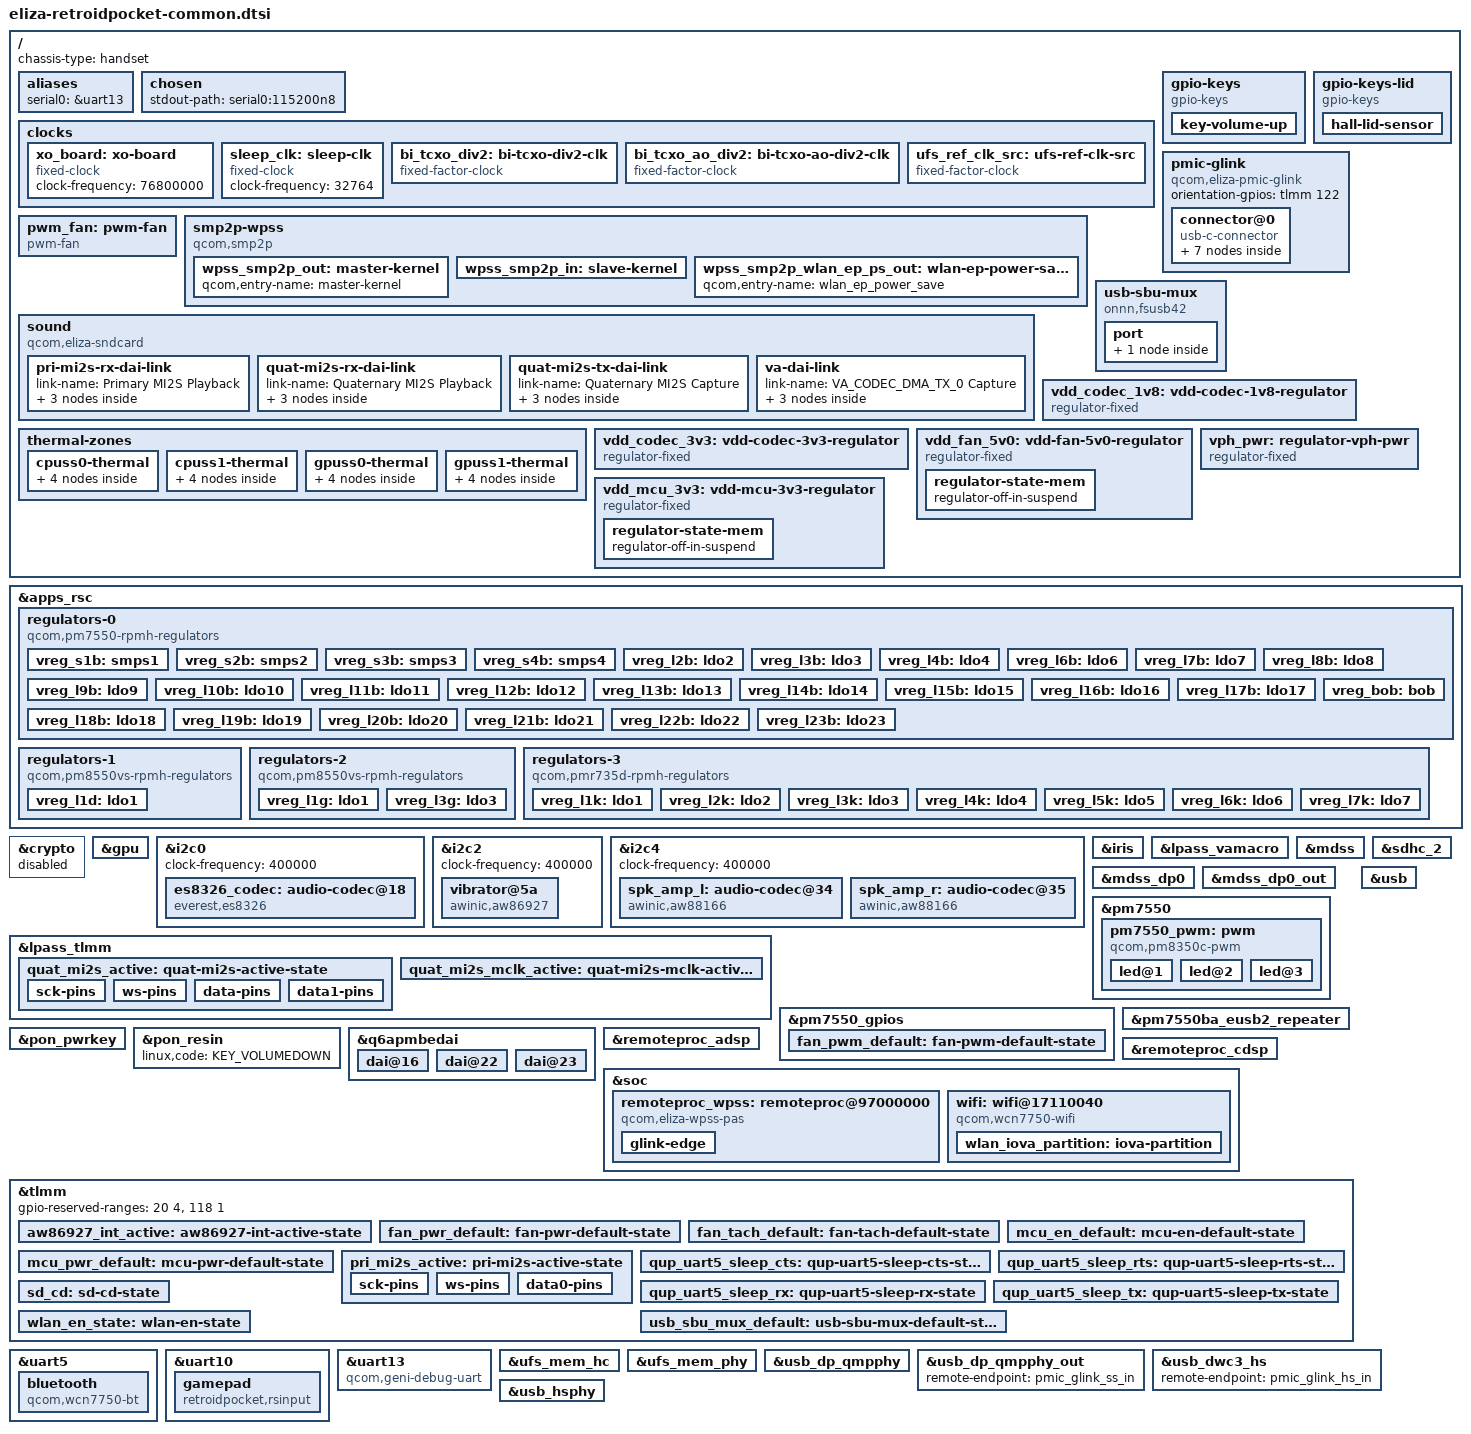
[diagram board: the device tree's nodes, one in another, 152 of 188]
// SPDX-License-Identifier: BSD-3-Clause
/*
 * Copyright (c) 2026, Teguh Sobirin.
 */

#include <dt-bindings/gpio/gpio.h>
#include <dt-bindings/leds/common.h>
#include <dt-bindings/pinctrl/qcom,pmic-gpio.h>
#include <dt-bindings/regulator/qcom,rpmh-regulator.h>
#include "eliza.dtsi"
#include "pm7550ba-eliza.dtsi"
#include "pm7550-eliza.dtsi"
#include "pm8550vs-d-eliza.dtsi"
#include "pm8550vs-g-eliza.dtsi"
#include "pmr735d-eliza.dtsi"
#include "pmk8550-eliza.dtsi"

/ {
	chassis-type = "handset";

	aliases {
		serial0 = &uart13;
	};

	chosen {
		stdout-path = "serial0:115200n8";
	};

	clocks {
		xo_board: xo-board {
			compatible = "fixed-clock";
			clock-frequency = <76800000>;
			#clock-cells = <0>;
		};

		sleep_clk: sleep-clk {
			compatible = "fixed-clock";
			clock-frequency = <32764>;
			#clock-cells = <0>;
		};

		bi_tcxo_div2: bi-tcxo-div2-clk {
			compatible = "fixed-factor-clock";
			#clock-cells = <0>;

			clocks = <&rpmhcc RPMH_CXO_CLK>;
			clock-mult = <1>;
			clock-div = <2>;
		};

		bi_tcxo_ao_div2: bi-tcxo-ao-div2-clk {
			compatible = "fixed-factor-clock";
			#clock-cells = <0>;

			clocks = <&rpmhcc RPMH_CXO_CLK_A>;
			clock-mult = <1>;
			clock-div = <2>;
		};

		ufs_ref_clk_src: ufs-ref-clk-src {
			compatible = "fixed-factor-clock";
			#clock-cells = <0>;

			clocks = <&rpmhcc RPMH_LN_BB_CLK3>;
			clock-mult = <1>;
			clock-div = <2>;
		};
	};

	gpio-keys {
		compatible = "gpio-keys";

		key-volume-up {
			label = "Volume Up";
			linux,code = <KEY_VOLUMEUP>;
			gpios = <&pm7550_gpios 6 GPIO_ACTIVE_LOW>;
			debounce-interval = <10>;
			linux,can-disable;
			wakeup-source;
		};
	};

	gpio-keys-lid {
		compatible = "gpio-keys";

		hall-lid-sensor {
			label = "Hall Lid Sensor";
			gpios = <&tlmm 31 GPIO_ACTIVE_LOW>;
			linux,input-type = <EV_SW>;
			linux,code = <SW_LID>;
			linux,can-disable;
			wakeup-source;
		};
	};

	pmic-glink {
		compatible = "qcom,eliza-pmic-glink",
			     "qcom,sm8550-pmic-glink",
			     "qcom,pmic-glink";
		#address-cells = <1>;
		#size-cells = <0>;
		orientation-gpios = <&tlmm 122 GPIO_ACTIVE_HIGH>;

		connector@0 {
			compatible = "usb-c-connector";
			reg = <0>;

			power-role = "dual";
			data-role = "dual";

			ports {
				#address-cells = <1>;
				#size-cells = <0>;

				port@0 {
					reg = <0>;

					pmic_glink_hs_in: endpoint {
						remote-endpoint = <&usb_dwc3_hs>;
					};
				};

				port@1 {
					reg = <1>;

					pmic_glink_ss_in: endpoint {
						remote-endpoint = <&usb_dp_qmpphy_out>;
					};
				};

				port@2 {
					reg = <2>;

					pmic_glink_sbu: endpoint {
						remote-endpoint = <&usb_sbu_mux_endpoint>;
					};
				};
			};
		};
	};

	pwm_fan: pwm-fan {
		compatible = "pwm-fan";

		fan-supply = <&vdd_fan_5v0>;
		pwms = <&pm7550_pwm 3 40000>;

		cooling-levels = <0 30 45 60 70 90 120 150>;
		#cooling-cells = <2>;

		pinctrl-names = "default";
		pinctrl-0 = <&fan_pwm_default>, <&fan_tach_default>;

		pulses-per-revolution = <2>;
		interrupt-parent = <&tlmm>;
		interrupts = <3 IRQ_TYPE_EDGE_FALLING>;
	};

	smp2p-wpss {
		compatible = "qcom,smp2p";
		qcom,smem = <617>, <616>;

		interrupts-extended = <&ipcc IPCC_CLIENT_WPSS
					     IPCC_MPROC_SIGNAL_SMP2P
					     IRQ_TYPE_EDGE_RISING>;

		mboxes = <&ipcc IPCC_CLIENT_WPSS IPCC_MPROC_SIGNAL_SMP2P>;

		qcom,local-pid = <0>;
		qcom,remote-pid = <13>;

		wpss_smp2p_out: master-kernel {
			qcom,entry-name = "master-kernel";
			#qcom,smem-state-cells = <1>;
		};

		wpss_smp2p_in: slave-kernel {
			qcom,entry-name = "slave-kernel";
			interrupt-controller;
			#interrupt-cells = <2>;
		};

		wpss_smp2p_wlan_ep_ps_out: wlan-ep-power-save {
			qcom,entry-name = "wlan_ep_power_save";
			#qcom,smem-state-cells = <1>;
		};
	};

	sound {
		compatible = "qcom,eliza-sndcard", "qcom,sm8450-sndcard";
		model = "ELIZA-RetroidPocket-I2S";

		pinctrl-names = "default";
		pinctrl-0 = <&pri_mi2s_active>, <&quat_mi2s_active>,
			    <&quat_mi2s_mclk_active>;

		pri-mi2s-rx-dai-link {
			link-name = "Primary MI2S Playback";

			cpu {
				sound-dai = <&q6apmbedai PRIMARY_MI2S_RX>;
			};

			platform {
				sound-dai = <&q6apm>;
			};

			codec {
				sound-dai = <&spk_amp_l 0>, <&spk_amp_r 0>;
			};
		};

		quat-mi2s-rx-dai-link {
			link-name = "Quaternary MI2S Playback";

			cpu {
				sound-dai = <&q6apmbedai QUATERNARY_MI2S_RX>;
			};

			platform {
				sound-dai = <&q6apm>;
			};

			codec {
				sound-dai = <&es8326_codec>;
			};
		};

		quat-mi2s-tx-dai-link {
			link-name = "Quaternary MI2S Capture";

			cpu {
				sound-dai = <&q6apmbedai QUATERNARY_MI2S_TX>;
			};

			platform {
				sound-dai = <&q6apm>;
			};

			codec {
				sound-dai = <&es8326_codec>;
			};
		};

		va-dai-link {
			link-name = "VA_CODEC_DMA_TX_0 Capture";

			cpu {
				sound-dai = <&q6apmbedai VA_CODEC_DMA_TX_0>;
			};

			platform {
				sound-dai = <&q6apm>;
			};

			codec {
				sound-dai = <&lpass_vamacro 0>;
			};
		};
	};

	thermal-zones {
		cpuss0-thermal {
			trips {
				cpuss0_fan: fan-trip {
					temperature = <55000>;
					hysteresis = <5000>;
					type = "active";
				};
			};

			cooling-maps {
				map-fan {
					trip = <&cpuss0_fan>;
					cooling-device = <&pwm_fan THERMAL_NO_LIMIT THERMAL_NO_LIMIT>;
				};
			};
		};

		cpuss1-thermal {
			trips {
				cpuss1_fan: fan-trip {
					temperature = <55000>;
					hysteresis = <5000>;
					type = "active";
				};
			};

			cooling-maps {
				map-fan {
					trip = <&cpuss1_fan>;
					cooling-device = <&pwm_fan THERMAL_NO_LIMIT THERMAL_NO_LIMIT>;
				};
			};
		};

		gpuss0-thermal {
			trips {
				gpuss0_fan: fan-trip {
					temperature = <60000>;
					hysteresis = <5000>;
					type = "active";
				};
			};

			cooling-maps {
				map-fan {
					trip = <&gpuss0_fan>;
					cooling-device = <&pwm_fan THERMAL_NO_LIMIT THERMAL_NO_LIMIT>;
				};
			};
		};

		gpuss1-thermal {
			trips {
				gpuss1_fan: fan-trip {
					temperature = <60000>;
					hysteresis = <5000>;
					type = "active";
				};
			};

			cooling-maps {
				map-fan {
					trip = <&gpuss1_fan>;
					cooling-device = <&pwm_fan THERMAL_NO_LIMIT THERMAL_NO_LIMIT>;
				};
			};
		};
	};

	/*
	 * DP AUX (SBU1/SBU2) analog switch, controlled by the same two GPIOs
	 * the vendor DP driver drives: gpio75 = output enable (driven low
	 * when DP is active), gpio76 = SBU lane select, high for a flipped
	 * (CC2) plug. The exact switch part is not known; the driver only
	 * binds against the generic gpio-sbu-mux compatible.
	 */
	usb-sbu-mux {
		compatible = "onnn,fsusb42", "gpio-sbu-mux";

		enable-gpios = <&tlmm 75 GPIO_ACTIVE_LOW>;
		select-gpios = <&tlmm 76 GPIO_ACTIVE_HIGH>;

		pinctrl-names = "default";
		pinctrl-0 = <&usb_sbu_mux_default>;

		mode-switch;
		orientation-switch;

		port {
			usb_sbu_mux_endpoint: endpoint {
				remote-endpoint = <&pmic_glink_sbu>;
			};
		};
	};

	vdd_codec_1v8: vdd-codec-1v8-regulator {
		compatible = "regulator-fixed";
		regulator-name = "vdd_codec_1v8";

		regulator-min-microvolt = <1800000>;
		regulator-max-microvolt = <1800000>;

		gpio = <&tlmm 163 GPIO_ACTIVE_HIGH>;
		enable-active-high;
	};

	vdd_codec_3v3: vdd-codec-3v3-regulator {
		compatible = "regulator-fixed";
		regulator-name = "vdd_codec_3v3";

		regulator-min-microvolt = <3300000>;
		regulator-max-microvolt = <3300000>;

		gpio = <&tlmm 164 GPIO_ACTIVE_HIGH>;
		enable-active-high;
	};

	vdd_fan_5v0: vdd-fan-5v0-regulator {
		compatible = "regulator-fixed";
		regulator-name = "vdd_fan_5v0";

		regulator-min-microvolt = <5000000>;
		regulator-max-microvolt = <5000000>;

		gpio = <&tlmm 55 GPIO_ACTIVE_HIGH>;
		enable-active-high;

		pinctrl-names = "default";
		pinctrl-0 = <&fan_pwr_default>;

		regulator-state-mem {
			regulator-off-in-suspend;
		};
	};

	vdd_mcu_3v3: vdd-mcu-3v3-regulator {
		compatible = "regulator-fixed";
		regulator-name = "vdd_mcu_3v3";

		regulator-min-microvolt = <3300000>;
		regulator-max-microvolt = <3300000>;

		gpio = <&tlmm 54 GPIO_ACTIVE_HIGH>;
		enable-active-high;

		pinctrl-names = "default";
		pinctrl-0 = <&mcu_pwr_default>;

		regulator-state-mem {
			regulator-off-in-suspend;
		};
	};

	vph_pwr: regulator-vph-pwr {
		compatible = "regulator-fixed";

		regulator-name = "vph_pwr";
		regulator-min-microvolt = <3700000>;
		regulator-max-microvolt = <3700000>;

		regulator-always-on;
		regulator-boot-on;
	};
};

&apps_rsc {
	regulators-0 {
		compatible = "qcom,pm7550-rpmh-regulators";

		vdd-l1-supply = <&vreg_s3b>;
		vdd-l2-l3-supply = <&vreg_s3b>;
		vdd-l4-l5-supply = <&vreg_s2b>;
		vdd-l6-supply = <&vreg_s2b>;
		vdd-l7-supply = <&vreg_s1b>;
		vdd-l8-supply = <&vreg_s1b>;
		vdd-l9-l10-supply = <&vreg_s1b>;
		vdd-l11-supply = <&vreg_s1b>;
		vdd-l12-l14-supply = <&vreg_bob>;
		vdd-l13-l16-supply = <&vreg_bob>;
		vdd-l15-l17-l18-l19-l20-l21-l22-l23-supply = <&vreg_bob>;
		vdd-s1-supply = <&vph_pwr>;
		vdd-s2-supply = <&vph_pwr>;
		vdd-s3-supply = <&vph_pwr>;
		vdd-s4-supply = <&vph_pwr>;
		vdd-s5-supply = <&vph_pwr>;
		vdd-s6-supply = <&vph_pwr>;

		vdd-bob-supply = <&vph_pwr>;

		qcom,pmic-id = "b";

		vreg_s1b: smps1 {
			regulator-name = "vreg_s1b";
			regulator-min-microvolt = <1856000>;
			regulator-max-microvolt = <2040000>;
			regulator-initial-mode = <RPMH_REGULATOR_MODE_HPM>;
		};

		vreg_s2b: smps2 {
			regulator-name = "vreg_s2b";
			regulator-min-microvolt = <1256000>;
			regulator-max-microvolt = <1408000>;
			regulator-initial-mode = <RPMH_REGULATOR_MODE_HPM>;
		};

		vreg_s3b: smps3 {
			regulator-name = "vreg_s3b";
			regulator-min-microvolt = <880000>;
			regulator-max-microvolt = <1040000>;
			regulator-initial-mode = <RPMH_REGULATOR_MODE_HPM>;
		};

		vreg_s4b: smps4 {
			regulator-name = "vreg_s4b";
			regulator-min-microvolt = <2156000>;
			regulator-max-microvolt = <2600000>;
			regulator-initial-mode = <RPMH_REGULATOR_MODE_HPM>;
		};

		vreg_l2b: ldo2 {
			regulator-name = "vreg_l2b";
			regulator-min-microvolt = <720000>;
			regulator-max-microvolt = <950000>;
			regulator-initial-mode = <RPMH_REGULATOR_MODE_HPM>;
		};

		vreg_l3b: ldo3 {
			regulator-name = "vreg_l3b";
			regulator-min-microvolt = <880000>;
			regulator-max-microvolt = <912000>;
			regulator-initial-mode = <RPMH_REGULATOR_MODE_HPM>;
		};

		vreg_l4b: ldo4 {
			regulator-name = "vreg_l4b";
			regulator-min-microvolt = <1200000>;
			regulator-max-microvolt = <1200000>;
			regulator-initial-mode = <RPMH_REGULATOR_MODE_HPM>;
		};

		vreg_l6b: ldo6 {
			regulator-name = "vreg_l6b";
			regulator-min-microvolt = <866000>;
			regulator-max-microvolt = <958000>;
			regulator-initial-mode = <RPMH_REGULATOR_MODE_HPM>;
		};

		vreg_l7b: ldo7 {
			regulator-name = "vreg_l7b";
			regulator-min-microvolt = <1800000>;
			regulator-max-microvolt = <1800000>;
			regulator-initial-mode = <RPMH_REGULATOR_MODE_HPM>;
		};

		vreg_l8b: ldo8 {
			regulator-name = "vreg_l8b";
			regulator-min-microvolt = <1800000>;
			regulator-max-microvolt = <1800000>;
			regulator-initial-mode = <RPMH_REGULATOR_MODE_HPM>;
		};

		vreg_l9b: ldo9 {
			regulator-name = "vreg_l9b";
			regulator-min-microvolt = <1800000>;
			regulator-max-microvolt = <1800000>;
			regulator-initial-mode = <RPMH_REGULATOR_MODE_HPM>;
		};

		vreg_l10b: ldo10 {
			regulator-name = "vreg_l10b";
			regulator-min-microvolt = <1800000>;
			regulator-max-microvolt = <1800000>;
			regulator-initial-mode = <RPMH_REGULATOR_MODE_HPM>;
		};

		vreg_l11b: ldo11 {
			regulator-name = "vreg_l11b";
			regulator-min-microvolt = <1800000>;
			regulator-max-microvolt = <1800000>;
			regulator-initial-mode = <RPMH_REGULATOR_MODE_HPM>;
		};

		vreg_l12b: ldo12 {
			regulator-name = "vreg_l12b";
			/* Voltage range for UFS 3.x and above */
			regulator-min-microvolt = <2400000>;
			regulator-max-microvolt = <3300000>;
			regulator-initial-mode = <RPMH_REGULATOR_MODE_HPM>;
		};

		vreg_l13b: ldo13 {
			regulator-name = "vreg_l13b";
			regulator-min-microvolt = <2700000>;
			regulator-max-microvolt = <3300000>;
			regulator-initial-mode = <RPMH_REGULATOR_MODE_HPM>;
		};

		vreg_l14b: ldo14 {
			regulator-name = "vreg_l14b";
			regulator-min-microvolt = <3300000>;
			regulator-max-microvolt = <3304000>;
			regulator-initial-mode = <RPMH_REGULATOR_MODE_HPM>;
		};

		vreg_l15b: ldo15 {
			regulator-name = "vreg_l15b";
			regulator-min-microvolt = <3300000>;
			regulator-max-microvolt = <3304000>;
			regulator-initial-mode = <RPMH_REGULATOR_MODE_HPM>;
		};

		vreg_l16b: ldo16 {
			regulator-name = "vreg_l16b";
			regulator-min-microvolt = <3008000>;
			regulator-max-microvolt = <3008000>;
			regulator-initial-mode = <RPMH_REGULATOR_MODE_HPM>;
		};

		vreg_l17b: ldo17 {
			regulator-name = "vreg_l17b";
			regulator-min-microvolt = <3104000>;
			regulator-max-microvolt = <3104000>;
			regulator-initial-mode = <RPMH_REGULATOR_MODE_HPM>;
		};

		vreg_l18b: ldo18 {
			regulator-name = "vreg_l18b";
			regulator-min-microvolt = <2800000>;
			regulator-max-microvolt = <2800000>;
			regulator-initial-mode = <RPMH_REGULATOR_MODE_HPM>;
		};

		vreg_l19b: ldo19 {
			regulator-name = "vreg_l19b";
			regulator-min-microvolt = <3000000>;
			regulator-max-microvolt = <3000000>;
			regulator-initial-mode = <RPMH_REGULATOR_MODE_HPM>;
		};

		vreg_l20b: ldo20 {
			regulator-name = "vreg_l20b";
			regulator-min-microvolt = <1620000>;
			regulator-max-microvolt = <3544000>;
			regulator-initial-mode = <RPMH_REGULATOR_MODE_HPM>;
		};

		vreg_l21b: ldo21 {
			regulator-name = "vreg_l21b";
			regulator-min-microvolt = <1620000>;
			regulator-max-microvolt = <3544000>;
			regulator-initial-mode = <RPMH_REGULATOR_MODE_HPM>;
		};

		vreg_l22b: ldo22 {
			regulator-name = "vreg_l22b";
			regulator-min-microvolt = <2700000>;
			regulator-max-microvolt = <3400000>;
			regulator-initial-mode = <RPMH_REGULATOR_MODE_HPM>;
		};

		vreg_l23b: ldo23 {
			regulator-name = "vreg_l23b";
			regulator-min-microvolt = <1650000>;
			regulator-max-microvolt = <3544000>;
			regulator-initial-mode = <RPMH_REGULATOR_MODE_HPM>;
		};

		vreg_bob: bob {
			regulator-name = "vreg_bob";
			regulator-min-microvolt = <3008000>;
			regulator-max-microvolt = <3960000>;
			regulator-initial-mode = <RPMH_REGULATOR_MODE_HPM>;
		};
	};

	regulators-1 {
		compatible = "qcom,pm8550vs-rpmh-regulators";

		vdd-l1-supply = <&vreg_s1b>;

		qcom,pmic-id = "d";

		vreg_l1d: ldo1 {
			regulator-name = "vreg_l1d";
			regulator-min-microvolt = <1800000>;
			regulator-max-microvolt = <1800000>;
			regulator-initial-mode = <RPMH_REGULATOR_MODE_HPM>;
		};
	};

	regulators-2 {
		compatible = "qcom,pm8550vs-rpmh-regulators";

		vdd-l1-supply = <&vreg_s2b>;
		vdd-l3-supply = <&vreg_s2b>;

		qcom,pmic-id = "g";

		vreg_l1g: ldo1 {
			regulator-name = "vreg_l1g";
			regulator-min-microvolt = <1150000>;
			regulator-max-microvolt = <1260000>;
			regulator-initial-mode = <RPMH_REGULATOR_MODE_HPM>;
		};

		vreg_l3g: ldo3 {
			regulator-name = "vreg_l3g";
			regulator-min-microvolt = <1150000>;
			regulator-max-microvolt = <1260000>;
			regulator-initial-mode = <RPMH_REGULATOR_MODE_HPM>;
		};

	};

	regulators-3 {
		compatible = "qcom,pmr735d-rpmh-regulators";

		vdd-l1-l2-l5-supply = <&vreg_s3b>;
		vdd-l3-l4-supply = <&vreg_s2b>;
		vdd-l6-supply = <&vreg_s1b>;
		vdd-l7-supply = <&vreg_s3b>;

		qcom,pmic-id = "k";

		vreg_l1k: ldo1 {
			regulator-name = "vreg_l1k";
			regulator-min-microvolt = <488000>;
			regulator-max-microvolt = <912000>;
			regulator-initial-mode = <RPMH_REGULATOR_MODE_HPM>;
		};

		vreg_l2k: ldo2 {
			regulator-name = "vreg_l2k";
			regulator-min-microvolt = <920000>;
			regulator-max-microvolt = <969000>;
			regulator-initial-mode = <RPMH_REGULATOR_MODE_HPM>;
		};

		vreg_l3k: ldo3 {
			regulator-name = "vreg_l3k";
			regulator-min-microvolt = <1080000>;
			regulator-max-microvolt = <1350000>;
			regulator-initial-mode = <RPMH_REGULATOR_MODE_HPM>;
		};

		vreg_l4k: ldo4 {
			regulator-name = "vreg_l4k";
			regulator-min-microvolt = <960000>;
			regulator-max-microvolt = <1200000>;
			regulator-initial-mode = <RPMH_REGULATOR_MODE_HPM>;
		};

		vreg_l5k: ldo5 {
			regulator-name = "vreg_l5k";
			regulator-min-microvolt = <866000>;
			regulator-max-microvolt = <931000>;
			regulator-initial-mode = <RPMH_REGULATOR_MODE_HPM>;
		};

		vreg_l6k: ldo6 {
			regulator-name = "vreg_l6k";
			regulator-min-microvolt = <1100000>;
			regulator-max-microvolt = <2000000>;
			regulator-initial-mode = <RPMH_REGULATOR_MODE_HPM>;
		};

		vreg_l7k: ldo7 {
			regulator-name = "vreg_l7k";
			regulator-min-microvolt = <720000>;
			regulator-max-microvolt = <958000>;
			regulator-initial-mode = <RPMH_REGULATOR_MODE_HPM>;
		};
	};
};

/* the QCE driver is marked BROKEN, keep the node from blocking sync_state */
&crypto {
	status = "disabled";
};

&gpu {
	status = "okay";
};

&i2c0 {
	clock-frequency = <400000>;
	status = "okay";

	es8326_codec: audio-codec@18 {
		compatible = "everest,es8326";
		reg = <0x18>;

		clocks = <&q6prmcc LPASS_CLK_ID_MCLK_3 LPASS_CLK_ATTRIBUTE_COUPLE_NO>;
		clock-names = "mclk";
		assigned-clocks = <&q6prmcc LPASS_CLK_ID_MCLK_3 LPASS_CLK_ATTRIBUTE_COUPLE_NO>;
		assigned-clock-rates = <12288000>;

		interrupt-parent = <&tlmm>;
		interrupts = <98 IRQ_TYPE_EDGE_RISING>;

		vdd-supply = <&vdd_codec_3v3>;
		vddio-supply = <&vdd_codec_1v8>;

		everest,jack-detect-inverted;
		everest,interrupt-src = /bits/ 8 <0x08>;
		everest,interrupt-clk = /bits/ 8 <0x00>;

		#sound-dai-cells = <0>;
	};
};

&i2c2 {
	clock-frequency = <400000>;
	status = "okay";

	vibrator@5a {
		compatible = "awinic,aw86927";
		reg = <0x5a>;

		interrupts-extended = <&tlmm 125 IRQ_TYPE_EDGE_FALLING>;
		reset-gpios = <&tlmm 68 GPIO_ACTIVE_LOW>;

		pinctrl-0 = <&aw86927_int_active>;
		pinctrl-names = "default";
	};
};

&i2c4 {
	clock-frequency = <400000>;
	status = "okay";

	spk_amp_l: audio-codec@34 {
		compatible = "awinic,aw88166";
		reg = <0x34>;
		#sound-dai-cells = <1>;
		reset-gpios = <&tlmm 127 GPIO_ACTIVE_LOW>;
		awinic,audio-channel = <1>;
		awinic,sync-flag;
		sound-name-prefix = "SPK_L";
	};

	spk_amp_r: audio-codec@35 {
		compatible = "awinic,aw88166";
		reg = <0x35>;
		#sound-dai-cells = <1>;
		reset-gpios = <&tlmm 126 GPIO_ACTIVE_LOW>;
		awinic,audio-channel = <0>;
		awinic,sync-flag;
		sound-name-prefix = "SPK_R";
	};
};

&iris {
	status = "okay";
};

&lpass_tlmm {
	quat_mi2s_active: quat-mi2s-active-state {
		sck-pins {
			pins = "gpio0";
			function = "i2s0_clk";
			drive-strength = <8>;
			bias-disable;
			output-high;
		};

		ws-pins {
			pins = "gpio1";
			function = "i2s0_ws";
			drive-strength = <8>;
			bias-disable;
			output-high;
		};

		data-pins {
			pins = "gpio2";
			function = "i2s0_data";
			drive-strength = <8>;
			bias-disable;
		};

		data1-pins {
			pins = "gpio3";
			function = "i2s0_data";
			drive-strength = <8>;
			bias-disable;
		};
	};

	quat_mi2s_mclk_active: quat-mi2s-mclk-active-state {
		pins = "gpio5";
		function = "ext_mclk1_c";
		drive-strength = <8>;
		bias-disable;
		output-high;
	};
};

&lpass_vamacro {
	pinctrl-names = "default";
	pinctrl-0 = <&dmic01_default>;

	vdd-micb-supply = <&vreg_l7b>;
	qcom,dmic-sample-rate = <4800000>;
};

&mdss {
	status = "okay";
};

&mdss_dp0 {
	status = "okay";
};

&mdss_dp0_out {
	link-frequencies = /bits/ 64 <1620000000 2700000000 5400000000 8100000000>;
};

&pm7550 {
	pm7550_pwm: pwm {
		compatible = "qcom,pm8350c-pwm";
		#address-cells = <1>;
		#size-cells = <0>;
		#pwm-cells = <2>;
		status = "okay";

		led@1 {
			reg = <1>;
			color = <LED_COLOR_ID_RED>;
			function = LED_FUNCTION_CHARGING;
			linux,default-trigger = "qcom-battmgr-bat-charging";
		};

		led@2 {
			reg = <2>;
			color = <LED_COLOR_ID_GREEN>;
			function = LED_FUNCTION_CHARGING;
			linux,default-trigger = "qcom-battmgr-bat-full";
		};

		led@3 {
			reg = <3>;
			color = <LED_COLOR_ID_BLUE>;
			function = LED_FUNCTION_STATUS;
		};
	};
};

&pm7550_gpios {
	fan_pwm_default: fan-pwm-default-state {
		pins = "gpio8";
		function = "func1";
		input-disable;
		output-enable;
		output-low;
		bias-disable;
		power-source = <1>;
	};
};

&pm7550ba_eusb2_repeater {
	vdd18-supply = <&vreg_l7b>;
	vdd3-supply = <&vreg_l17b>;
};

&pon_pwrkey {
	status = "okay";
};

&pon_resin {
	linux,code = <KEY_VOLUMEDOWN>;
	status = "okay";
};

&q6apmbedai {
	#address-cells = <1>;
	#size-cells = <0>;

	dai@16 {
		reg = <PRIMARY_MI2S_RX>;
		clocks = <&q6prmcc LPASS_CLK_ID_MCLK_1 LPASS_CLK_ATTRIBUTE_COUPLE_NO>,
			 <&q6prmcc LPASS_CLK_ID_PRI_MI2S_IBIT LPASS_CLK_ATTRIBUTE_COUPLE_NO>;
		clock-names = "mclk", "bclk";
	};

	dai@22 {
		reg = <QUATERNARY_MI2S_RX>;
		clocks = <&q6prmcc LPASS_CLK_ID_MCLK_3 LPASS_CLK_ATTRIBUTE_COUPLE_NO>,
			 <&q6prmcc LPASS_CLK_ID_QUAD_MI2S_IBIT LPASS_CLK_ATTRIBUTE_COUPLE_NO>;
		clock-names = "mclk", "bclk";
	};

	dai@23 {
		reg = <QUATERNARY_MI2S_TX>;
		clocks = <&q6prmcc LPASS_CLK_ID_MCLK_3 LPASS_CLK_ATTRIBUTE_COUPLE_NO>,
			 <&q6prmcc LPASS_CLK_ID_QUAD_MI2S_IBIT LPASS_CLK_ATTRIBUTE_COUPLE_NO>;
		clock-names = "mclk", "bclk";
	};
};

&remoteproc_adsp {
	status = "okay";
};

&remoteproc_cdsp {
	status = "okay";
};

&sdhc_2 {
	vmmc-supply = <&vreg_l13b>;
	vqmmc-supply = <&vreg_l23b>;

	cd-gpios = <&tlmm 58 GPIO_ACTIVE_LOW>;

	pinctrl-0 = <&sdc2_default>, <&sd_cd>;
	pinctrl-1 = <&sdc2_sleep>, <&sd_cd>;
	pinctrl-names = "default", "sleep";

	status = "okay";
};

&soc {
	/*
	 * WCN7750: the WLAN Q6 runs on the WPSS remoteproc (downstream
	 * kera-wcn7750, icnss2), booted by ath12k through qcom,rproc.
	 */
	remoteproc_wpss: remoteproc@97000000 {
		compatible = "qcom,eliza-wpss-pas", "qcom,sc7280-wpss-pas";
		reg = <0x0 0x97000000 0x0 0x10000>;

		interrupts-extended = <&intc GIC_SPI 200 IRQ_TYPE_EDGE_RISING>,
				      <&wpss_smp2p_in 0 IRQ_TYPE_EDGE_RISING>,
				      <&wpss_smp2p_in 1 IRQ_TYPE_EDGE_RISING>,
				      <&wpss_smp2p_in 2 IRQ_TYPE_EDGE_RISING>,
				      <&wpss_smp2p_in 3 IRQ_TYPE_EDGE_RISING>,
				      <&wpss_smp2p_in 7 IRQ_TYPE_EDGE_RISING>;
		interrupt-names = "wdog",
				  "fatal",
				  "ready",
				  "handover",
				  "stop-ack",
				  "shutdown-ack";

		clocks = <&rpmhcc RPMH_CXO_CLK>;
		clock-names = "xo";

		power-domains = <&rpmhpd RPMHPD_CX>,
				<&rpmhpd RPMHPD_MX>;
		power-domain-names = "cx",
				     "mx";

		memory-region = <&wpss_mem>;

		qcom,qmp = <&aoss_qmp>;

		qcom,smem-states = <&wpss_smp2p_out 0>;
		qcom,smem-state-names = "stop";

		status = "okay";

		glink-edge {
			interrupts-extended = <&ipcc IPCC_CLIENT_WPSS
						     IPCC_MPROC_SIGNAL_GLINK_QMP
						     IRQ_TYPE_EDGE_RISING>;
			mboxes = <&ipcc IPCC_CLIENT_WPSS
					IPCC_MPROC_SIGNAL_GLINK_QMP>;

			label = "wpss";
			qcom,remote-pid = <13>;
		};
	};

	wifi: wifi@17110040 {
		compatible = "qcom,wcn7750-wifi";
		/* MSI write target; the register BAR is reported over QMI */
		reg = <0x0 0x17110040 0x0 0x0>;
		reg-names = "msi_addr";

		/* MSI vectors: 10 CE + 18 DP */
		interrupts = <GIC_SPI 768 IRQ_TYPE_EDGE_RISING>,
			     <GIC_SPI 769 IRQ_TYPE_EDGE_RISING>,
			     <GIC_SPI 770 IRQ_TYPE_EDGE_RISING>,
			     <GIC_SPI 771 IRQ_TYPE_EDGE_RISING>,
			     <GIC_SPI 772 IRQ_TYPE_EDGE_RISING>,
			     <GIC_SPI 773 IRQ_TYPE_EDGE_RISING>,
			     <GIC_SPI 774 IRQ_TYPE_EDGE_RISING>,
			     <GIC_SPI 775 IRQ_TYPE_EDGE_RISING>,
			     <GIC_SPI 776 IRQ_TYPE_EDGE_RISING>,
			     <GIC_SPI 777 IRQ_TYPE_EDGE_RISING>,
			     <GIC_SPI 778 IRQ_TYPE_EDGE_RISING>,
			     <GIC_SPI 779 IRQ_TYPE_EDGE_RISING>,
			     <GIC_SPI 780 IRQ_TYPE_EDGE_RISING>,
			     <GIC_SPI 781 IRQ_TYPE_EDGE_RISING>,
			     <GIC_SPI 782 IRQ_TYPE_EDGE_RISING>,
			     <GIC_SPI 783 IRQ_TYPE_EDGE_RISING>,
			     <GIC_SPI 784 IRQ_TYPE_EDGE_RISING>,
			     <GIC_SPI 785 IRQ_TYPE_EDGE_RISING>,
			     <GIC_SPI 786 IRQ_TYPE_EDGE_RISING>,
			     <GIC_SPI 787 IRQ_TYPE_EDGE_RISING>,
			     <GIC_SPI 788 IRQ_TYPE_EDGE_RISING>,
			     <GIC_SPI 789 IRQ_TYPE_EDGE_RISING>,
			     <GIC_SPI 790 IRQ_TYPE_EDGE_RISING>,
			     <GIC_SPI 791 IRQ_TYPE_EDGE_RISING>,
			     <GIC_SPI 792 IRQ_TYPE_EDGE_RISING>,
			     <GIC_SPI 793 IRQ_TYPE_EDGE_RISING>,
			     <GIC_SPI 794 IRQ_TYPE_EDGE_RISING>,
			     <GIC_SPI 795 IRQ_TYPE_EDGE_RISING>,
			     <GIC_SPI 796 IRQ_TYPE_EDGE_RISING>,
			     <GIC_SPI 797 IRQ_TYPE_EDGE_RISING>,
			     <GIC_SPI 798 IRQ_TYPE_EDGE_RISING>,
			     <GIC_SPI 799 IRQ_TYPE_EDGE_RISING>;

		iommus = <&apps_smmu 0x1480 0x1>;
		dma-coherent;

		/* PCIe -> DDR path the companion die masters through */
		interconnects = <&pcie_noc MASTER_PCIE_0 QCOM_ICC_TAG_ALWAYS
				 &mc_virt SLAVE_EBI1 QCOM_ICC_TAG_ALWAYS>;
		interconnect-names = "pcie-mem";

		/* shared with Bluetooth, which enables them without a voltage */
		vdd-cx-mx-supply = <&vreg_s3b>;
		vdd-1.8-xo-supply = <&vreg_s1b>;
		vdd-1.3-rfa-supply = <&vreg_s2b>;
		vdd-1.8-io-supply = <&vreg_l11b>;

		qcom,rproc = <&remoteproc_wpss>;

		/* WLAN_EN, driven by the driver once the rails are up */
		wlan-en-gpios = <&tlmm 35 GPIO_ACTIVE_HIGH>;
		pinctrl-names = "default";
		pinctrl-0 = <&wlan_en_state>;

		/* wlan-en, bt-en, host-sol, dev-sol, sw-ctrl, reset-b */
		qcom,gpio-info = <35 0xffff 33 32 81 0xffff>;

		/*
		 * The die reaches host memory through a 256 MB window; the IOVA
		 * partition below confines the DMA allocator to it (downstream
		 * qcom,iommu-geometry 0xb0000000+0x10010000) and is what
		 * host_cap ddr_range reports, together with the MSA carveout.
		 */
		memory-region = <&wlan_iova_partition>, <&wlan_msa_mem>;
		memory-region-names = "iova-partition", "msa";

		/* endpoint power save on the internal PCIe link */
		qcom,smem-states = <&wpss_smp2p_wlan_ep_ps_out 0>;
		qcom,smem-state-names = "wlan-ep-powersave-smp2p-out";

		/* kera-wcn7750.dtsi qcom,pdc_init_table */
		qcom,qmp = <&aoss_qmp>;
		qcom,pdc-init-table =
			" {class: wlan_pdc, ss: rf, res: s3b.v, dwnval: 696}",
			" {class: wlan_pdc, ss: rf, res: s1b.v, upval: 1864}",
			" {class: wlan_pdc, ss: rf, res: s2b.v, upval: 1316}",
			" {class: wlan_pdc, ss: rf, res: s4b.e, enable: 0}";

		status = "okay";

		wlan_iova_partition: iova-partition {
			iommu-addresses = <&wifi 0x0 0x00000000 0x0 0xb0000000>,
					  <&wifi 0x0 0xc0010000 0x0 0x3fff0000>;
		};
	};
};

&tlmm {
	gpio-reserved-ranges = <20 4>,   /* NFC SPI */
			       <118 1>;  /* NFC Secure I/O */

	aw86927_int_active: aw86927-int-active-state {
		pins = "gpio125";
		function = "gpio";
		drive-strength = <2>;
		bias-pull-up;
	};

	fan_pwr_default: fan-pwr-default-state {
		pins = "gpio55";
		function = "gpio";
		drive-strength = <2>;
		bias-disable;
		output-low;
	};

	fan_tach_default: fan-tach-default-state {
		pins = "gpio3";
		function = "gpio";
		drive-strength = <2>;
		bias-pull-up;
		input-enable;
	};

	mcu_en_default: mcu-en-default-state {
		pins = "gpio56";
		function = "gpio";
		bias-pull-down;
	};

	mcu_pwr_default: mcu-pwr-default-state {
		pins = "gpio54";
		function = "gpio";
		drive-strength = <2>;
		bias-disable;
		output-low;
	};

	pri_mi2s_active: pri-mi2s-active-state {
		sck-pins {
			pins = "gpio60";
			function = "i2s0_sck";
			drive-strength = <8>;
			bias-disable;
			output-high;
		};

		ws-pins {
			pins = "gpio61";
			function = "i2s0_ws";
			drive-strength = <8>;
			bias-disable;
			output-high;
		};

		data0-pins {
			pins = "gpio64";
			function = "i2s0_data0";
			drive-strength = <8>;
			bias-disable;
		};
	};

	qup_uart5_sleep_cts: qup-uart5-sleep-cts-state {
		pins = "gpio132";
		function = "gpio";
		bias-bus-hold;
	};

	qup_uart5_sleep_rts: qup-uart5-sleep-rts-state {
		pins = "gpio133";
		function = "gpio";
		bias-pull-down;
	};

	qup_uart5_sleep_rx: qup-uart5-sleep-rx-state {
		pins = "gpio135";
		function = "gpio";
		bias-pull-up;
	};

	qup_uart5_sleep_tx: qup-uart5-sleep-tx-state {
		pins = "gpio134";
		function = "gpio";
		bias-pull-up;
	};

	sd_cd: sd-cd-state {
		pins = "gpio58";
		function = "gpio";
		bias-pull-up;
	};

	usb_sbu_mux_default: usb-sbu-mux-default-state {
		pins = "gpio75", "gpio76";
		function = "gpio";
		drive-strength = <8>;
		bias-disable;
	};

	wlan_en_state: wlan-en-state {
		pins = "gpio35";
		function = "gpio";
		drive-strength = <16>;
		bias-pull-up;
	};
};

&uart5 {
	/delete-property/ interrupts;
	interrupts-extended = <&intc GIC_SPI 358 IRQ_TYPE_LEVEL_HIGH>,
			      <&tlmm 135 IRQ_TYPE_EDGE_FALLING>;

	pinctrl-0 = <&qup_uart5_default>, <&qup_uart5_cts_rts>;
	pinctrl-1 = <&qup_uart5_sleep_cts>, <&qup_uart5_sleep_rts>,
		    <&qup_uart5_sleep_tx>, <&qup_uart5_sleep_rx>;
	pinctrl-names = "default", "sleep";

	status = "okay";

	bluetooth: bluetooth {
		compatible = "qcom,wcn7750-bt";

		clocks = <&rpmhcc RPMH_RF_CLK1>;

		enable-gpios = <&pm8550vs_g_gpios 4 GPIO_ACTIVE_HIGH>;
		swctrl-gpios = <&tlmm 81 GPIO_ACTIVE_HIGH>;

		vddio-supply = <&vreg_l7b>;
		vddaon-supply = <&vreg_l11b>;
		vdddig-supply = <&vreg_s3b>;
		vddrfacmn-supply = <&vreg_s3b>;
		vddrfa0p8-supply = <&vreg_l6k>;
		vddrfa1p2-supply = <&vreg_s2b>;
		vddrfa1p9-supply = <&vreg_s1b>;
		vddrfa2p2-supply = <&vreg_s4b>;

		max-speed = <3200000>;
	};
};

&uart10 {
	status = "okay";

	gamepad: gamepad {
		compatible = "retroidpocket,rsinput";

		gamepad-name = "RetroidPocket Gamepad";
		gamepad-bus = <0x0003>;
		gamepad-vid = <0x2020>;
		gamepad-pid = <0x3001>;
		gamepad-rev = <0x0001>;

		vdd-supply = <&vdd_mcu_3v3>;
		enable-gpios = <&tlmm 56 GPIO_ACTIVE_HIGH>;
		pinctrl-0 = <&mcu_en_default>;
		pinctrl-names = "default";
	};
};

&uart13 {
	compatible = "qcom,geni-debug-uart";

	status = "okay";
};

&ufs_mem_hc {
	reset-gpios = <&tlmm 185 GPIO_ACTIVE_LOW>;

	/*
	 * Legacy doorbell mode only: without the "mcq" region ufs-qcom cannot
	 * set up MCQ and ufshcd falls back to SDB (nutrs = 32). This device is
	 * a UFS 2.2 part with shared queueing (bQueueDepth 32); in MCQ mode
	 * ufshcd_lu_init() gives every LU a depth of 64 and the device answers
	 * with TASK SET FULL (seen as OCS_MISMATCH_RESP_UPIU_SIZE).
	 */
	reg = <0x0 0x01d84000 0x0 0x3000>;
	reg-names = "std";

	vcc-supply = <&vreg_l12b>;
	vcc-max-microamp = <1300000>;
	vccq-supply = <&vreg_l1d>;
	vccq-max-microamp = <1200000>;

	/* SKhynix H9HQ15A is a UFS 2.x part, max HS-G3; skip G4/G5 attempts */
	limit-hs-gear = <3>;

	/*
	 * Override the UFS clock list solely to swap ref_clk to the 19.2 MHz
	 * ufs_ref_clk_src (LN_BB_CLK3 / 2). Feeding LN_BB_CLK3 directly makes
	 * ufshcd program bRefClkFreq=38.4 MHz and storm HS-G3. Order/names must
	 * match eliza.dtsi; clock-names is inherited unchanged.
	 */
	clocks = <&gcc GCC_UFS_PHY_AXI_CLK>,
		 <&gcc GCC_AGGRE_UFS_PHY_AXI_CLK>,
		 <&gcc GCC_UFS_PHY_AHB_CLK>,
		 <&gcc GCC_UFS_PHY_UNIPRO_CORE_CLK>,
		 <&ufs_ref_clk_src>,
		 <&gcc GCC_UFS_PHY_TX_SYMBOL_0_CLK>,
		 <&gcc GCC_UFS_PHY_RX_SYMBOL_0_CLK>,
		 <&gcc GCC_UFS_PHY_RX_SYMBOL_1_CLK>;

	status = "okay";
};

&ufs_mem_phy {
	vdda-phy-supply = <&vreg_l6b>;
	vdda-pll-supply = <&vreg_l4b>;

	status = "okay";
};

&usb {
	status = "okay";
};

&usb_dp_qmpphy {
	vdda-phy-supply = <&vreg_l7k>;
	vdda-pll-supply = <&vreg_l3g>;

	status = "okay";
};

&usb_dp_qmpphy_out {
	remote-endpoint = <&pmic_glink_ss_in>;
};

&usb_dwc3_hs {
	remote-endpoint = <&pmic_glink_hs_in>;
};

&usb_hsphy {
	vdd-supply = <&vreg_l7k>;
	vdda12-supply = <&vreg_l4b>;

	phys = <&pm7550ba_eusb2_repeater>;

	status = "okay";
};
